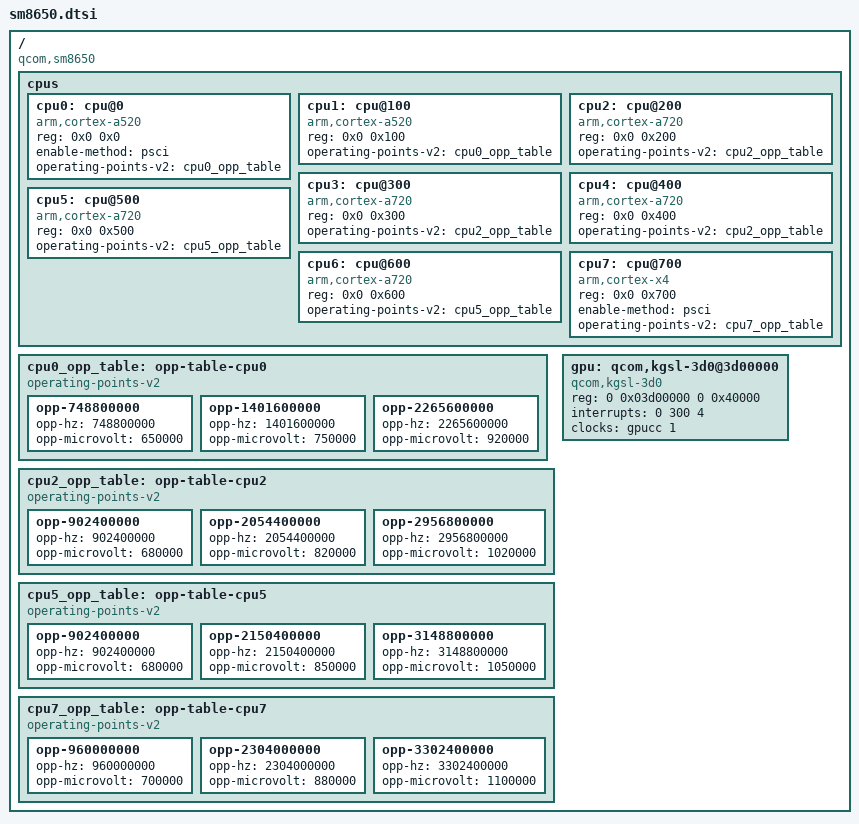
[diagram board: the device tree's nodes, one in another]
// SPDX-License-Identifier: GPL-2.0
/*
 * Qualcomm Technologies, Inc. SM8650 (Snapdragon 8 Gen 3)
 * Reference: Xiaomi 14 / 14 Pro (Houji / Shennong)
 * Source: MiCode/Xiaomi_Kernel_OpenSource (houji-u-oss)
 */

/ {
	compatible = "qcom,sm8650";
	#address-cells = <2>;
	#size-cells = <2>;

	cpus {
		#address-cells = <2>;
		#size-cells = <0>;

		/* Silver: 2x Cortex-A520 up to 2.26 GHz */
		cpu0: cpu@0 {
			device_type = "cpu";
			compatible = "arm,cortex-a520";
			reg = <0x0 0x0>;
			enable-method = "psci";
			operating-points-v2 = <&cpu0_opp_table>;
		};
		cpu1: cpu@100 {
			device_type = "cpu";
			compatible = "arm,cortex-a520";
			reg = <0x0 0x100>;
			operating-points-v2 = <&cpu0_opp_table>;
		};

		/* Gold: 5x Cortex-A720 up to 3.15 GHz */
		cpu2: cpu@200 {
			device_type = "cpu";
			compatible = "arm,cortex-a720";
			reg = <0x0 0x200>;
			operating-points-v2 = <&cpu2_opp_table>;
		};
		cpu3: cpu@300 {
			device_type = "cpu";
			compatible = "arm,cortex-a720";
			reg = <0x0 0x300>;
			operating-points-v2 = <&cpu2_opp_table>;
		};
		cpu4: cpu@400 {
			device_type = "cpu";
			compatible = "arm,cortex-a720";
			reg = <0x0 0x400>;
			operating-points-v2 = <&cpu2_opp_table>;
		};
		cpu5: cpu@500 {
			device_type = "cpu";
			compatible = "arm,cortex-a720";
			reg = <0x0 0x500>;
			operating-points-v2 = <&cpu5_opp_table>;
		};
		cpu6: cpu@600 {
			device_type = "cpu";
			compatible = "arm,cortex-a720";
			reg = <0x0 0x600>;
			operating-points-v2 = <&cpu5_opp_table>;
		};

		/* Prime: 1x Cortex-X4 up to 3.3 GHz */
		cpu7: cpu@700 {
			device_type = "cpu";
			compatible = "arm,cortex-x4";
			reg = <0x0 0x700>;
			enable-method = "psci";
			operating-points-v2 = <&cpu7_opp_table>;
		};
	};

	cpu0_opp_table: opp-table-cpu0 {
		compatible = "operating-points-v2";
		opp-748800000  { opp-hz = /bits/ 64 <748800000>;  opp-microvolt = <650000>; };
		opp-1401600000 { opp-hz = /bits/ 64 <1401600000>; opp-microvolt = <750000>; };
		opp-2265600000 { opp-hz = /bits/ 64 <2265600000>; opp-microvolt = <920000>; };
	};

	cpu2_opp_table: opp-table-cpu2 {
		compatible = "operating-points-v2";
		opp-902400000  { opp-hz = /bits/ 64 <902400000>;  opp-microvolt = <680000>; };
		opp-2054400000 { opp-hz = /bits/ 64 <2054400000>; opp-microvolt = <820000>; };
		opp-2956800000 { opp-hz = /bits/ 64 <2956800000>; opp-microvolt = <1020000>; };
	};

	cpu5_opp_table: opp-table-cpu5 {
		compatible = "operating-points-v2";
		opp-902400000  { opp-hz = /bits/ 64 <902400000>;  opp-microvolt = <680000>; };
		opp-2150400000 { opp-hz = /bits/ 64 <2150400000>; opp-microvolt = <850000>; };
		opp-3148800000 { opp-hz = /bits/ 64 <3148800000>; opp-microvolt = <1050000>; };
	};

	cpu7_opp_table: opp-table-cpu7 {
		compatible = "operating-points-v2";
		opp-960000000  { opp-hz = /bits/ 64 <960000000>;  opp-microvolt = <700000>; };
		opp-2304000000 { opp-hz = /bits/ 64 <2304000000>; opp-microvolt = <880000>; };
		opp-3302400000 { opp-hz = /bits/ 64 <3302400000>; opp-microvolt = <1100000>; };
	};

	/* Adreno 750 GPU */
	gpu: qcom,kgsl-3d0@3d00000 {
		compatible = "qcom,kgsl-3d0", "qcom,adreno-750";
		reg = <0 0x03d00000 0 0x40000>;
		interrupts = <0 300 4>;
		clocks = <&gpucc 1>;
		clock-names = "core_clk";
	};
};
